# YTM32B1MC0 register map
Vendor: YTMicro; File version: 1.0
CPU: CM33 r0p4, little endian, MPU, FPU, 2 interrupt priority bits
Registers are 32-bit, read-write, reset 0x0 unless marked. A register's access mark holds for its fields unless they carry their own. Offsets are from the block's base; [hi:lo] are bit positions; {n}, {i} and the like mark numbered series; 'fields as' and 'values as' point back to an identical list; <NAME> marks a mode.

## EFM
Base 0x40010000; register names take the prefix EFM_
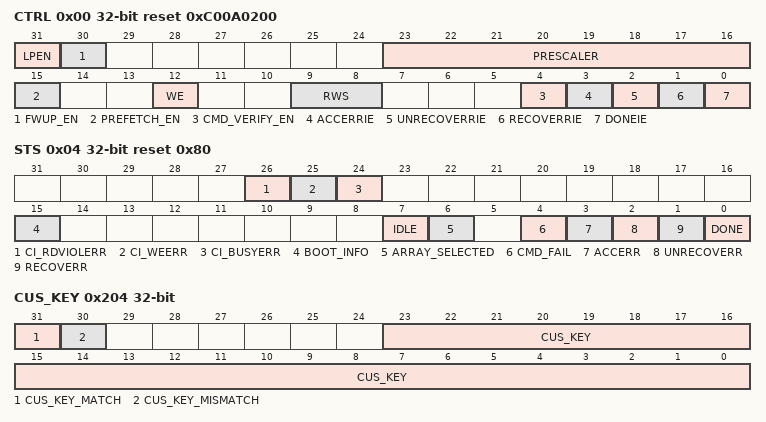
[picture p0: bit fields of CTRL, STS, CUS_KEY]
0x00 CTRL reset 0xC00A0200
  [31] LPEN — This LPEN bit determines whether the Flash array will enter low power mode when the MCU send a sleep request.
    0=Flash will keep active when the MCU send a sleep request; 1=Flash will enter low power mode when the MCU send a sleep request
  [30] FWUP_EN — This FWUP_EN bit determines whether enables fast wake-up of the Flash array. Power consumption of fast wake-up is bigger than normal wake-up.
    0=Flash wake-up time from Deep Standby mode is 20us; 1=Flash wake-up time from Deep Standby mode is 10us
  [23:16] PRESCALER — These PRESCALER bits are used for EFM operation time control. ewline Please use the following equation to calculate the PRESCALER value: ewline PRESCALER = slow bus clock frequency / 2 ewline Round up if not divisible. ewline The unit of slow bus clock frequency is Mhz. ewline For example, if slow bus clock frequency is 40Mhz, PRESCALER value should be 20. ewline Please re-configure PRESCALER once the frequency is changed.
  [15] PREFETCH_EN — This PREFETCH_EN bit is used to enable pre-fetch function. ewline EFM pre-fetch the data in Flash address+1 when the Flash array is free. Then if bus read address+1 happens, pre-fetch hit, bus get Flash data without waiting for Flash access time. ewline Only PFlash0 and PFlash1 supports pre-fetch function, bus read of NVR array will ignore this register bit.
    0=Disable pre-fetch function; 1=Enable pre-fetch function
  [12] WE — This WE bit determines whether Flash is writable. Write Flash when WE is 0 causes bus error and STS[CI_WEERR] flag is set at the same time.
    0=Disable Flash write; 1=Enable Flash write
  [9:8] RWS
    1=core clk <= 60Mhz; 2=60Mhz < core clk <=80Mhz
  [4] CMD_VERIFY_EN — This CMD_VERIFY_EN bit determines whether to do verify read after erase or program operation during executing a command. ewline - After each program cycle, if CMD_VERIFY_EN=1, EFM should read the programmed address and compare the read data to program data, if not equal, set STS[CMD_FAIL] flag to 1. ewline - After each erase cycle, if CMD_VERIFY_EN=1, EFM should read the erased addresses and compare read data with FF, if read data are not all FF, set STS[CMD_FAIL] flag to 1.
    0=Disable verify read after erase or program cycle; 1=Enable verify read after erase or program cycle
  [3] ACCERRIE — This ACCERRIE bit determines whether the interrupt will be generated when STS[ACCERR] flag is asserted.
    0=Don't generate interrupt when STS[ACCERR] flag is asserted; 1=Generate interrupt when STS[ACCERR] flag is asserted
  [2] UNRECOVERRIE — This UNRECOVERRIE bit determines whether the interrupt will be generated when STS[UNRECOVERR] flag is asserted.
    0=Don't generate interrupt when STS[UNRECOVERR] flag is asserted; 1=Generate interrupt when STS[UNRECOVERR] flag is asserted
  [1] RECOVERRIE — This RECOVERRIE bit determines whether the interrupt will be generated when STS[RECOVERR] flag is asserted.
    0=Don't generate interrupt when STS[RECOVER] flag is asserted; 1=Generate interrupt when STS[RECOVERR] flag is asserted
  [0] DONEIE — This DONEIE bit determines whether the interrupt will be generated when DONE flag is asserted.
    0=Don't generate interrupt when STS[DONE] flag is asserted; 1=Generate interrupt when STS[DONE] flag is asserted
0x04 STS reset 0x80
  [26] CI_RDVIOLERR — This CI_RDVIOLERR bit indicates whether a read violation error is detected. Please check this bit after bus error. ewline Read violation error includes below scenarios: ewline - Read CUS_NVR sector when CUS_KEY is not set.; ewline - Read HCU_NVR sector; ewline - Read BOOT_NVR sector.
  [25] CI_WEERR — Try to write Flash array when CTRL[WE] is disabled will cause bus error and set CI_WEERR flag.
  [24] CI_BUSYERR — Try to access Flash array when CTRL[IDLE] is 0 will cause bus error and set CI_BUSYERR flag.
  [15] BOOT_INFO ro — This BOOT_INFO bit indicates whether address remap is enabled.
    0=Address remap is disabled; 1=Address remap is enabled. Refer to \hyperref[boot-swap-operation]{Boot-Swap Operation} for more details.
  [7] IDLE ro — This IDLE bit indicates whether EFM is busy executing a command.
    0=EFM is execting a command; 1=EFM is idle
  [6] ARRAY_SELECTED ro — Software should write target array address before launching a command. The write operation will set ARRAY_SELECTED flag after several cycles. ewline ote{Launching command when ARRAY_SELECTED=1 avoid access error caused by non-sequential scheduling of instructions.}
    0=The target Flash array is not selected. EFM is not ready to launch a command.; 1=The target Flash array is selected. EFM is ready to launch a command.
  [4] CMD_FAIL — This CMD_FAIL bit indicates whether the current command is failed. ewline Command failure includes below scenarios: ewline - Read check before a program cycle failed if data and ECC bits are not all FF. ewline - Verify check after a erase cycle failed if data and ECC bits are not cleared to all FF. ewline - Verify check after a program cycle failed if program data not equal to read data .
  [3] ACCERR — This ACCERR bit indicates whether an access error is detected. This flag is set after write EFM_CMD. When an access error occurred, the command is not launched. ewline Access error scenarios refer to \hyperref[flash-abnormal-operation]{Flash Abnormal Operation}.
    0=Access error is not detected; 1=Access error is detected
  [2] UNRECOVERR — This UNRECOVERR bit indicates whether a 2-bit ECC error is detected during Flash read.
    0=No un-recovery ECC error is detected; 1=2-bit ECC error is detected
  [1] RECOVERR — This RECOVERR bit indicates whether a 1-bit ECC error is detected during Flash read.
    0=No recovery ECC error is detected; 1=1-bit ECC error is detected
  [0] DONE — This DONE bit indicates whether the current command is completed.
    0=Current command is in progress; 1=Current command is completed
0x08 CMD
  [7:0] CMD — These CMD bits determine which commands are available. ewline
0x0C CMD_PROT
  [31:0] CMD_PROT — These CMD_PROT is used to disable commands. ewline Once the bit is set, corresponding command will be disable. The following table gives the map between commands and CMD_PROT bits ewline
0x10 TIMING1 reset 0xA
  [7:0] TPROG — These TPROG bits indicate the program pulse time. ewline The valid program pulse time is from 5us to 6.5us. The time unit of TPROG is 0.5us. So that the TPROG value range is 10 to 13. ewline For example, if TPROG value is 10, the Flash array program pulse time is 10*0.5us=5us.
0x14 TIMING2 reset 0xFA0
  [15:0] TERASE — These TERASE bits indicate the erase pulse times. ewline For Sector Erase, the valid erase pulse time is from 2ms to 3ms. ewline For Block Erase, the valid erase pulse time is from 30ms to 40ms. ewline The time unit of TERASE is 0.5us. For example, if TERASE value is 4000, the Flash array sector erase pulse time is 4000*0.5us=2ms. ote{Please set TERASE register to valid value before send ERASE_SECTOR or ERASE_BLOCK command.}
0x20 ERR_INJECT_CTRL
  [31:30] ECCERR_INJ_EN — Set this ECCERR_INJ_EN bits while cause 1-bit/ 2-bit ECC error for any Flash reading.
    0=00b (Disable ECC error inject .); 1=01b (Inject 1-bit ECC error.); 2=10b (Inject 1-bit ECC error.); 3=11b (Inject 2-bit ECC error.)
0x24 ADDR_PROT0 reset 0xFFFFFFFF
  [31:0] FLASH_ADDR_PROT — The address area of each PFlash is divided into 32 regions. Each region is protected by one bit of ADDR_PROT. The address area of each region is 4KB. ewline If any bit is set to 0, its corresponding region is under protection (read only). ewline EFM hardware initial flow (EFM_STS[IDLE]=0) will load ADDR_PROT registers with initial values from CUS_NVR array if the CUS_NVR has programmed with initial ADDR_PROT values and tag. ewline After EFM hardware initial done (EFM_STS[IDLE]=1), software can write 0 to value 1 bit of ADDR_PROT, but can not write 1 to value 0 bit. ewline The FLASH_ADDR_PROT protects SOC address space.
0x28 ADDR_PROT1 reset 0xFFFFFFFF
  fields as ADDR_PROT0
0x30 ECCERR_ADDR reset 0xFFFFFFFF
  [31:0] ERR_FLASH_ADDR ro — These bits records the first detected ECC error address. Followed ECC error addresses are not recorded. ewline When detecting an ECC error, hardware will set ECC error flag (RECOVERR or UNRECOVERR) and record information about error Flash address and error array. Read ECCERR_ADDR can get SOC address of the recorded ECC error. ewline ECCERR_ADDR is cleared by writing 1 to the corresponding error flag. For example, if ECCERR_ADDR records UNRECOVERR address information, only write 1 to UNRECOVERR can clear ECCERR_ADDR, writing 1 to RECOVERR can not clear ECCERR_ADDR. ewline ECCERR_ADDR is aligned to 8Byte because a FLash read get a 64-bit page data. When recorded an ECC error address in ECCERR_ADDR, any bus read of Flash address located in ECCERR_ADDR~(ECCERR_ADDR+0x7) will get ECC error too. ewline When STS[BOOT_SEL]=1 and recorded ECC error address located in PFlash or DFlash (refer to \hyperref[efm-memory-map]{EFM Memory Map}), software should re-map read ERR_FLASH_ADDR address to get true SOC address of ECC error Flash page. For example, when STS[BOOT_SEL]=1 ewline (1) if ERR_FLASH_ADDR=0x00000000, the true ECC error SOC address is 0x00000000 + 0x00020000=0x00020000 (PFlash0 SOC address remapped to PFLash1 physical array); ewline (2) if ERR_FLASH_ADDR=0x0003FFF8, the true ECC error SOC address is 0x0003FFF8 - 0x00020000=0x0001FFF8 (PFlash1 SOC address remapped to PFLash0 physical array); ewline (3) if ERR_FLASH_ADDR=0x100037F8, the true ECC error SOC address is 0x100037F8 + 0x00010000=0x100137F8 (DFlash0 SOC address remapped to DFLash1 physical array); ewline (4) if ERR_FLASH_ADDR=0x10011000, the true ECC error SOC address is 0x10011000 - 0x00010000=0x10001000 (DFlash1 SOC address remapped to DFLash0 physical array); ewline
0x34 ECCERR_CNT
  [13:0] ECCERR_CNT ro — These ECCERR_CNT bits record 1-bit and 2-bit ECC errors.
0x200 CMD_UNLOCK
  [31:0] CMD_UNLOCK_KEY wo — Please write 0xfd9573f5 before launching a command
0x204 CUS_KEY
  [31] CUS_KEY_MATCH ro — This CUS_KEY_MATCH bit indicates whether Customer Key is matched. ewline Write CUS_KEY with correct value when both CUS_KEY_MATCH and CUS_KEY_MISMATCH are low will set this flag high. ewline When CUS_KEY_MATCH is high, write error value to CUS_KEY will clear this flag. ewline When CUS_KEY_MISMATCH is high, this flag is low until a reset happened.
    0=Customer Key is not matched; 1=Customer Key is matched
  [30] CUS_KEY_MISMATCH ro — This CUS_KEY_MISMATCH bit indicates whether Customer Key is mis-matched. ewline Write CUS_KEY with error value when both CUS_KEY_MATCH and CUS_KEY_MISMATCH are low will set this bit to high. ewline When CUS_KEY_MISMATCH is high, CUS_KEY configuration is blocked. This flag can only be cleared by Power-on Reset.
    0=Customer Key is matched; 1=Customer Key is not matched
  [23:0] CUS_KEY wo — Following are Customer Key protected operations, please write CUS_KEY with correct value before doing these operations: ewline - Read or erase or program CUS_NVR if CUS_NVR exists. ewline - Erase HCU_NVR array if HCU_NVR exists. ewline Default Customer Key value is 0x4DFF32 and the Customer Key can be re-defined by programming the first address of CUS_NVR, it will be effective after EFM is reset.
